# EFR32FG1V131F256GM48 register map
File version: 3.0.0
CPU: CM4 r0p1, little endian, MPU, FPU, 3 interrupt priority bits
Registers are 32-bit, read-write, reset 0x0 unless marked. A register's access mark holds for its fields unless they carry their own. Offsets are from the block's base; [hi:lo] are bit positions; {n}, {i} and the like mark numbered series; 'fields as' and 'values as' point back to an identical list.

## DEVINFO
Base 0x0FE08000
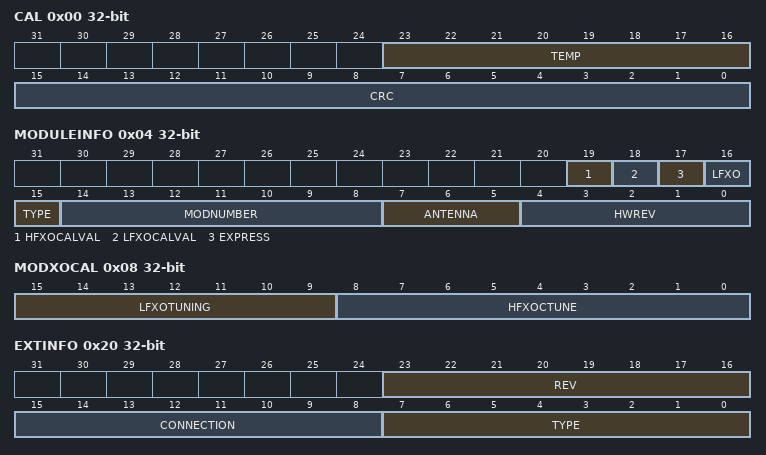
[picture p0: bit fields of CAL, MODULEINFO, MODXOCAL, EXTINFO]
0x00 CAL ro reset not defined
  [23:16] TEMP, [15:0] CRC
0x04 MODULEINFO ro reset not defined
  [19] HFXOCALVAL, [18] LFXOCALVAL, [17] EXPRESS, [16] LFXO, [15] TYPE, [14:8] MODNUMBER, [7:5] ANTENNA, [4:0] HWREV
0x08 MODXOCAL ro reset not defined
  [15:9] LFXOTUNING, [8:0] HFXOCTUNE
0x20 EXTINFO ro reset not defined
  [23:16] REV, [15:8] CONNECTION, [7:0] TYPE
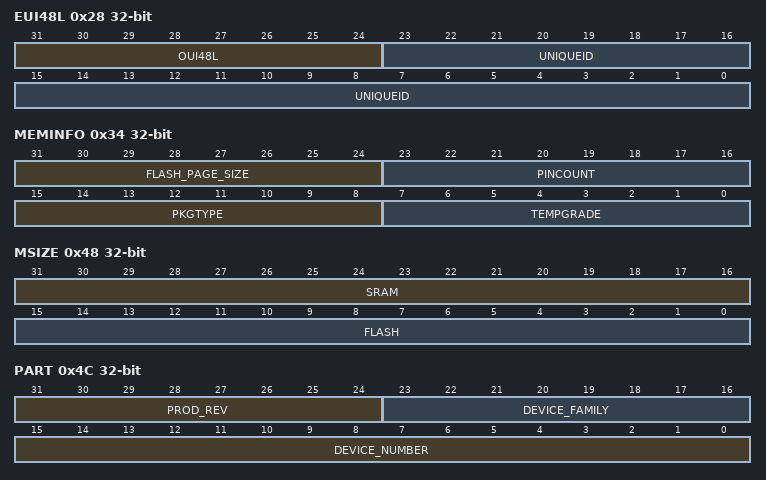
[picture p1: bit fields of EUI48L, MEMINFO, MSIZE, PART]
0x28 EUI48L ro reset not defined
  [31:24] OUI48L, [23:0] UNIQUEID
0x2C EUI48H ro reset not defined
  [15:0] OUI48H
0x30 CUSTOMINFO ro reset not defined
  [31:16] PARTNO
0x34 MEMINFO ro reset not defined
  [31:24] FLASH_PAGE_SIZE, [23:16] PINCOUNT, [15:8] PKGTYPE, [7:0] TEMPGRADE
0x40 UNIQUEL ro reset not defined
0x44 UNIQUEH ro reset not defined
0x48 MSIZE ro reset not defined
  [31:16] SRAM, [15:0] FLASH
0x4C PART ro reset not defined
  [31:24] PROD_REV, [23:16] DEVICE_FAMILY, [15:0] DEVICE_NUMBER
0x50 DEVINFOREV ro reset not defined
  [7:0] DEVINFOREV
0x54 EMUTEMP ro reset not defined
  [7:0] EMUTEMPROOM
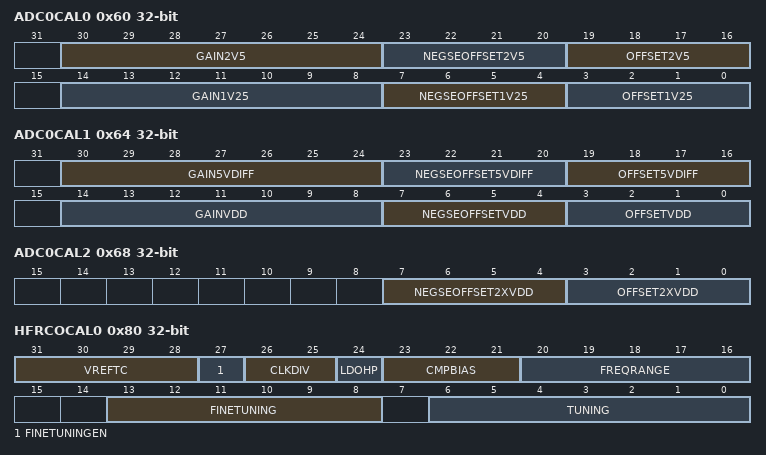
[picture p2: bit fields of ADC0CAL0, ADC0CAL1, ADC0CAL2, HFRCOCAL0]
0x60 ADC0CAL0 ro reset not defined
  [30:24] GAIN2V5, [23:20] NEGSEOFFSET2V5, [19:16] OFFSET2V5, [14:8] GAIN1V25, [7:4] NEGSEOFFSET1V25, [3:0] OFFSET1V25
0x64 ADC0CAL1 ro reset not defined
  [30:24] GAIN5VDIFF, [23:20] NEGSEOFFSET5VDIFF, [19:16] OFFSET5VDIFF, [14:8] GAINVDD, [7:4] NEGSEOFFSETVDD, [3:0] OFFSETVDD
0x68 ADC0CAL2 ro reset not defined
  [7:4] NEGSEOFFSET2XVDD, [3:0] OFFSET2XVDD
0x6C ADC0CAL3 ro reset not defined
  [15:4] TEMPREAD1V25
0x80 HFRCOCAL0 ro reset not defined
  [31:28] VREFTC, [27] FINETUNINGEN, [26:25] CLKDIV, [24] LDOHP, [23:21] CMPBIAS, [20:16] FREQRANGE, [13:8] FINETUNING, [6:0] TUNING
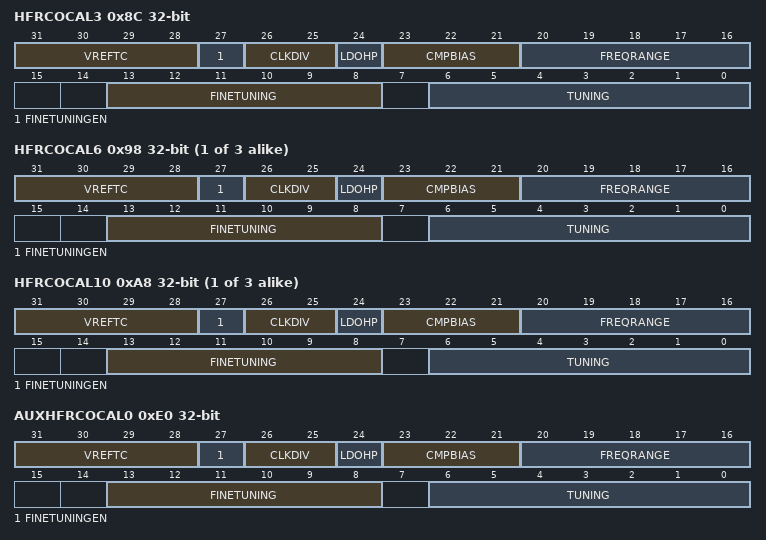
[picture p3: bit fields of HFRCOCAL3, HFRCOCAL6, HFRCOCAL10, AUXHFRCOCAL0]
0x8C HFRCOCAL3 ro reset not defined
  fields as HFRCOCAL0
{0x80+4i} HFRCOCAL{i} ro reset not defined (i=6..8)
  fields as HFRCOCAL0
{0x80+4i} HFRCOCAL{i} ro reset not defined (i=10..12)
  fields as HFRCOCAL0
0xE0 AUXHFRCOCAL0 ro reset not defined
  fields as HFRCOCAL0
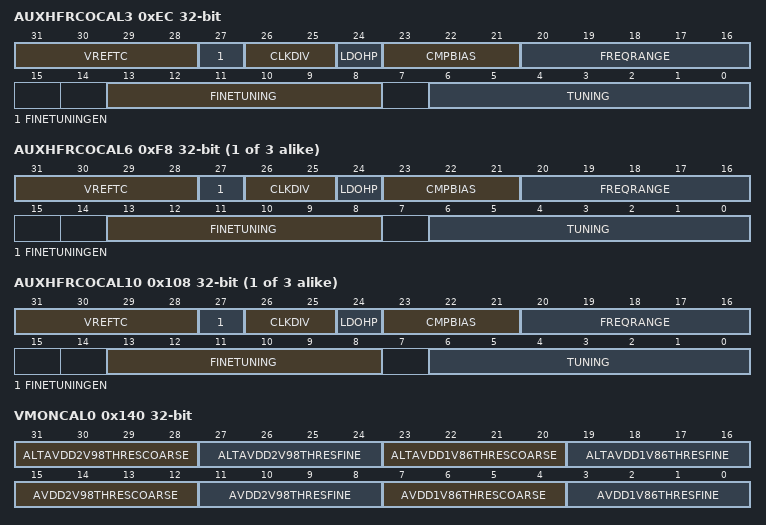
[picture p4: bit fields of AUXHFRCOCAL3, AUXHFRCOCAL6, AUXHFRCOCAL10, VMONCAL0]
0xEC AUXHFRCOCAL3 ro reset not defined
  fields as HFRCOCAL0
{0xE0+4i} AUXHFRCOCAL{i} ro reset not defined (i=6..8)
  fields as HFRCOCAL0
{0xE0+4i} AUXHFRCOCAL{i} ro reset not defined (i=10..12)
  fields as HFRCOCAL0
0x140 VMONCAL0 ro reset not defined
  [31:28] ALTAVDD2V98THRESCOARSE, [27:24] ALTAVDD2V98THRESFINE, [23:20] ALTAVDD1V86THRESCOARSE, [19:16] ALTAVDD1V86THRESFINE, [15:12] AVDD2V98THRESCOARSE, [11:8] AVDD2V98THRESFINE, [7:4] AVDD1V86THRESCOARSE, [3:0] AVDD1V86THRESFINE
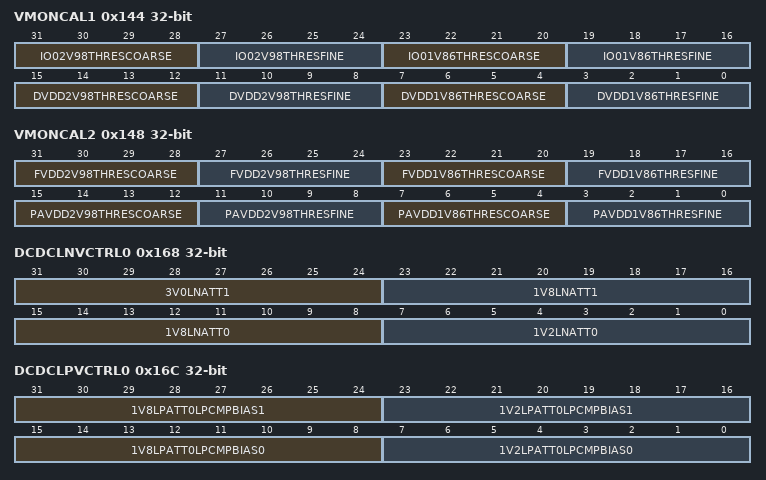
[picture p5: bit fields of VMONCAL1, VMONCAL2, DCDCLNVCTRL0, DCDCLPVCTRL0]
0x144 VMONCAL1 ro reset not defined
  [31:28] IO02V98THRESCOARSE, [27:24] IO02V98THRESFINE, [23:20] IO01V86THRESCOARSE, [19:16] IO01V86THRESFINE, [15:12] DVDD2V98THRESCOARSE, [11:8] DVDD2V98THRESFINE, [7:4] DVDD1V86THRESCOARSE, [3:0] DVDD1V86THRESFINE
0x148 VMONCAL2 ro reset not defined
  [31:28] FVDD2V98THRESCOARSE, [27:24] FVDD2V98THRESFINE, [23:20] FVDD1V86THRESCOARSE, [19:16] FVDD1V86THRESFINE, [15:12] PAVDD2V98THRESCOARSE, [11:8] PAVDD2V98THRESFINE, [7:4] PAVDD1V86THRESCOARSE, [3:0] PAVDD1V86THRESFINE
0x158 IDAC0CAL0 ro reset not defined
  [23:16] SOURCERANGE2TUNING, [15:8] SOURCERANGE1TUNING, [7:0] SOURCERANGE0TUNING, [7:0] SOURCERANGE3TUNING
0x15C IDAC0CAL1 ro reset not defined
  [23:16] SINKRANGE2TUNING, [15:8] SINKRANGE1TUNING, [7:0] SINKRANGE0TUNING, [7:0] SINKRANGE3TUNING
0x168 DCDCLNVCTRL0 ro reset not defined
  [31:24] 3V0LNATT1, [23:16] 1V8LNATT1, [15:8] 1V8LNATT0, [7:0] 1V2LNATT0
0x16C DCDCLPVCTRL0 ro reset not defined
  [31:24] 1V8LPATT0LPCMPBIAS1, [23:16] 1V2LPATT0LPCMPBIAS1, [15:8] 1V8LPATT0LPCMPBIAS0, [7:0] 1V2LPATT0LPCMPBIAS0
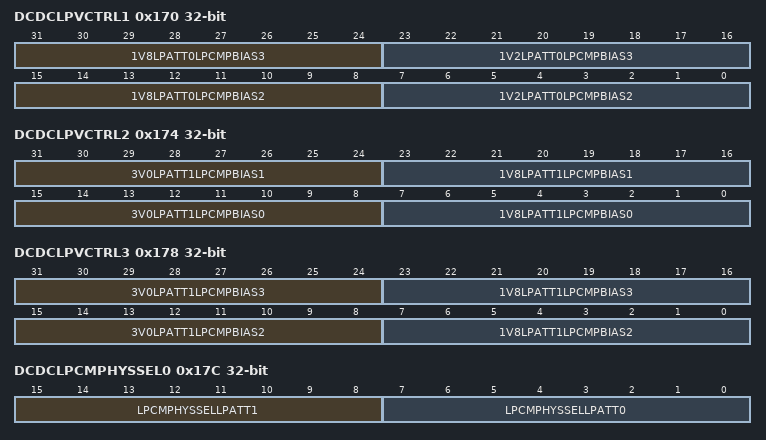
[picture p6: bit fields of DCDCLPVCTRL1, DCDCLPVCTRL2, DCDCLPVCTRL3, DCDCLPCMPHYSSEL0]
0x170 DCDCLPVCTRL1 ro reset not defined
  [31:24] 1V8LPATT0LPCMPBIAS3, [23:16] 1V2LPATT0LPCMPBIAS3, [15:8] 1V8LPATT0LPCMPBIAS2, [7:0] 1V2LPATT0LPCMPBIAS2
0x174 DCDCLPVCTRL2 ro reset not defined
  [31:24] 3V0LPATT1LPCMPBIAS1, [23:16] 1V8LPATT1LPCMPBIAS1, [15:8] 3V0LPATT1LPCMPBIAS0, [7:0] 1V8LPATT1LPCMPBIAS0
0x178 DCDCLPVCTRL3 ro reset not defined
  [31:24] 3V0LPATT1LPCMPBIAS3, [23:16] 1V8LPATT1LPCMPBIAS3, [15:8] 3V0LPATT1LPCMPBIAS2, [7:0] 1V8LPATT1LPCMPBIAS2
0x17C DCDCLPCMPHYSSEL0 ro reset not defined
  [15:8] LPCMPHYSSELLPATT1, [7:0] LPCMPHYSSELLPATT0
0x180 DCDCLPCMPHYSSEL1 ro reset not defined
  [15:8] LPCMPHYSSELLPCMPBIAS1, [7:0] LPCMPHYSSELLPCMPBIAS0, [7:0] LPCMPHYSSELLPCMPBIAS2, [7:0] LPCMPHYSSELLPCMPBIAS3
